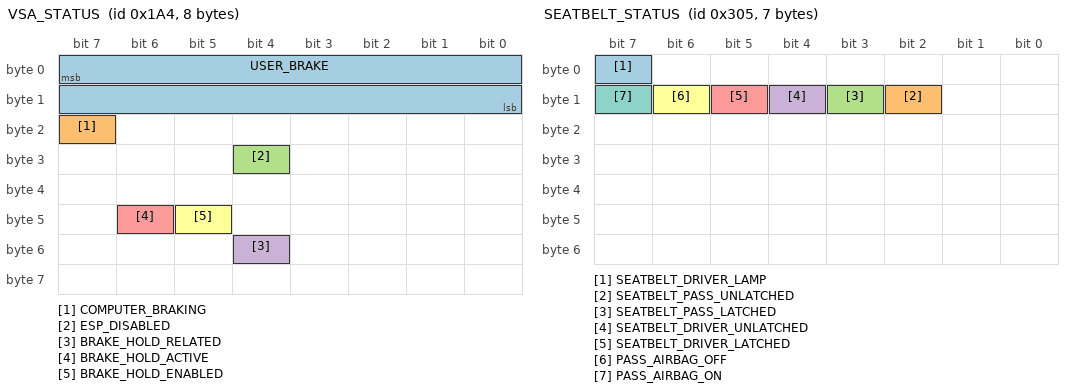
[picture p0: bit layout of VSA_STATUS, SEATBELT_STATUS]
BO_ 420 VSA_STATUS: 8 VSA
 SG_ USER_BRAKE : 7|16@0+ (1,0) [0|1000] "" EON
 SG_ COMPUTER_BRAKING : 23|1@0+ (1,0) [0|1] "" EON
 SG_ ESP_DISABLED : 28|1@0+ (1,0) [0|1] "" EON
 SG_ BRAKE_HOLD_RELATED : 52|1@0+ (1,0) [0|1] "" XXX
 SG_ BRAKE_HOLD_ACTIVE : 46|1@0+ (1,0) [0|1] "" EON
 SG_ BRAKE_HOLD_ENABLED : 45|1@0+ (1,0) [0|1] "" EON

BO_ 316 GAS_PEDAL: 8 PCM
 SG_ ENGINE_TORQUE_ESTIMATE : 7|16@0- (1,0) [-1000|1000] "Nm" EON
 SG_ ENGINE_TORQUE_REQUEST : 23|16@0- (1,0) [-1000|1000] "Nm" EON
 SG_ LOAD : 31|8@0- (1,0) [-1000|1000] "Nm" EON

BO_ 773 SEATBELT_STATUS: 7 BDY
 SG_ SEATBELT_DRIVER_LAMP : 7|1@0+ (1,0) [0|1] "" EON
 SG_ SEATBELT_PASS_UNLATCHED : 10|1@0+ (1,0) [0|1] "" EON
 SG_ SEATBELT_PASS_LATCHED : 11|1@0+ (1,0) [0|1] "" EON
 SG_ SEATBELT_DRIVER_UNLATCHED : 12|1@0+ (1,0) [0|1] "" EON
 SG_ SEATBELT_DRIVER_LATCHED : 13|1@0+ (1,0) [0|1] "" EON
 SG_ PASS_AIRBAG_OFF : 14|1@0+ (1,0) [0|1] "" EON
 SG_ PASS_AIRBAG_ON : 15|1@0+ (1,0) [0|1] "" EON

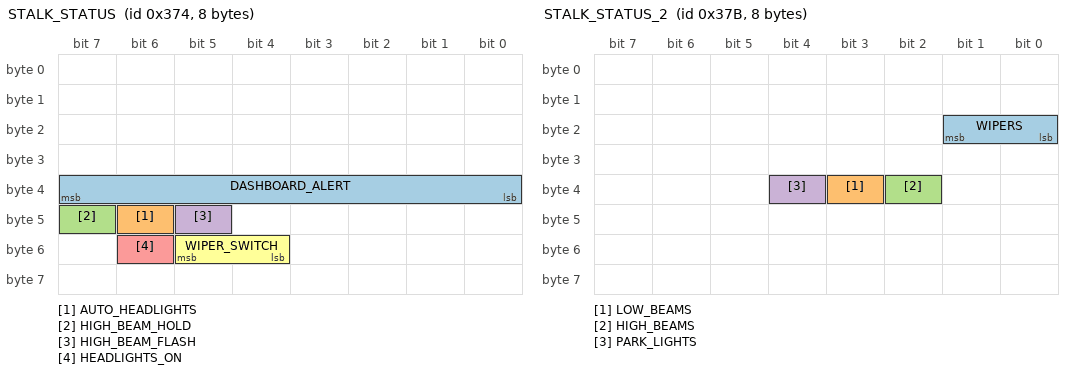
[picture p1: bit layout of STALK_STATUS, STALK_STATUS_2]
BO_ 884 STALK_STATUS: 8 XXX
 SG_ DASHBOARD_ALERT : 39|8@0+ (1,0) [0|255] "" EON
 SG_ AUTO_HEADLIGHTS : 46|1@0+ (1,0) [0|1] "" EON
 SG_ HIGH_BEAM_HOLD : 47|1@0+ (1,0) [0|1] "" EON
 SG_ HIGH_BEAM_FLASH : 45|1@0+ (1,0) [0|1] "" EON
 SG_ HEADLIGHTS_ON : 54|1@0+ (1,0) [0|1] "" EON
 SG_ WIPER_SWITCH : 53|2@0+ (1,0) [0|3] "" XXX

BO_ 891 STALK_STATUS_2: 8 XXX
 SG_ WIPERS : 17|2@0+ (1,0) [0|3] "" EON
 SG_ LOW_BEAMS : 35|1@0+ (1,0) [0|1] "" XXX
 SG_ HIGH_BEAMS : 34|1@0+ (1,0) [0|1] "" XXX
 SG_ PARK_LIGHTS : 36|1@0+ (1,0) [0|1] "" XXX

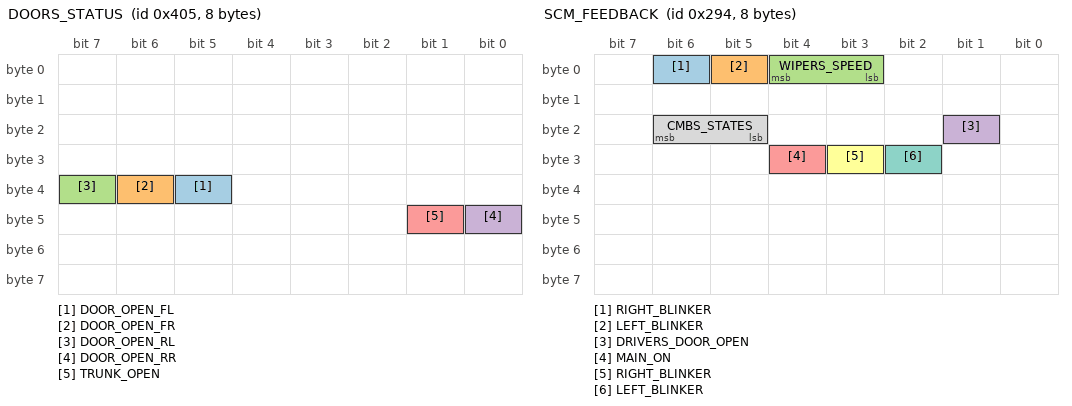
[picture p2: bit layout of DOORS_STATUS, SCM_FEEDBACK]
BO_ 1029 DOORS_STATUS: 8 BDY
 SG_ DOOR_OPEN_FL : 37|1@0+ (1,0) [0|1] "" EON
 SG_ DOOR_OPEN_FR : 38|1@0+ (1,0) [0|1] "" EON
 SG_ DOOR_OPEN_RL : 39|1@0+ (1,0) [0|1] "" EON
 SG_ DOOR_OPEN_RR : 40|1@0+ (1,0) [0|1] "" EON
 SG_ TRUNK_OPEN : 41|1@0+ (1,0) [0|1] "" EON

BO_ 777 LOCK_STATUS: 8 XXX
 SG_ DOORS_UNLOCKED : 54|1@0+ (1,0) [0|1] "" EON
 SG_ DOORS_LOCKED : 55|1@0+ (1,0) [0|1] "" EON

BO_ 918 FUEL: 8 PCM
 SG_ FUEL_TANK_LEVEL : 23|16@0+ (0.001,0) [0|65.535] "gal" EON

BO_ 145 STEERING_CONTROL: 8 EON
 SG_ STEER_ANGLE : 0|12@0+ (10.8,-1382.4) [0|255] "deg" SCM

VAL_ 422 CRUISE_BUTTONS 4 "accel_res" 3 "decel_set" 2 "cancel" 1 "main" 0 "none" ;
VAL_ 422 LIGHTS_SETTING 3 "high_beam" 2 "low_beam" 1 "position" 0 "no_lights" ;
VAL_ 422 AC_COMPRESSOR 0 "off" 4 "on";

BO_ 892 CRUISE_PARAMS: 8 PCM
 SG_ CRUISE_SPEED_OFFSET : 31|8@0- (0.1,0) [-128|127] "kph" EON

BO_ 660 SCM_FEEDBACK: 8 SCM
 SG_ RIGHT_BLINKER : 6|1@0+ (1,0) [0|1] "" EON
 SG_ LEFT_BLINKER : 5|1@0+ (1,0) [0|1] "" EON
 SG_ WIPERS_SPEED : 4|2@0+ (1,0) [0|3] "" EON

 SG_ DRIVERS_DOOR_OPEN : 17|1@0+ (1,0) [0|1] "" XXX
 SG_ MAIN_ON : 28|1@0+ (1,0) [0|1] "" EON
 SG_ RIGHT_BLINKER : 27|1@0+ (1,0) [0|1] "" EON
 SG_ LEFT_BLINKER : 26|1@0+ (1,0) [0|1] "" EON
 SG_ CMBS_STATES : 22|2@0+ (1,0) [0|3] "" EON

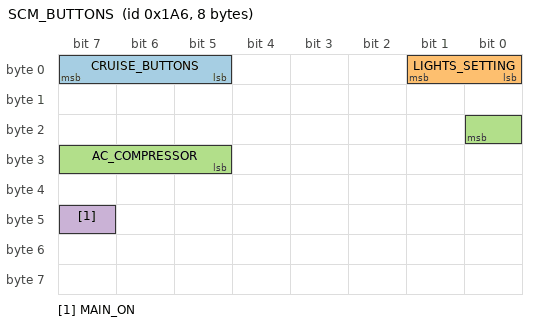
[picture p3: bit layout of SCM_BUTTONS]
BO_ 422 SCM_BUTTONS: 8 SCM
 SG_ CRUISE_BUTTONS : 7|3@0+ (1,0) [0|7] "" EON
 SG_ LIGHTS_SETTING : 1|2@0+ (1,0) [0|3] "" EON
 SG_ AC_COMPRESSOR : 16|4@0+ (1,0) [0|15] "" EON
 SG_ MAIN_ON : 47|1@0+ (1,0) [0|1] "" EON
